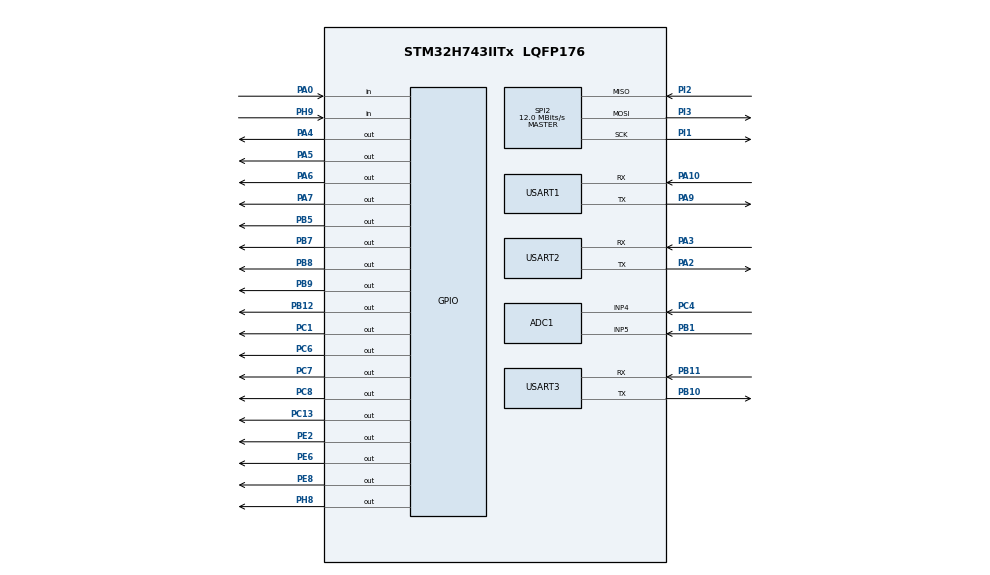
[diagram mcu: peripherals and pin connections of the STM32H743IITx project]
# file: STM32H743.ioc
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ADC1.Channel-0\#ChannelRegularConversion=ADC_CHANNEL_4
ADC1.ClockPrescaler=ADC_CLOCK_ASYNC_DIV1
ADC1.ConversionDataManagement=ADC_CONVERSIONDATA_DMA_ONESHOT
ADC1.ExternalTrigConv=ADC_EXTERNALTRIG_T3_TRGO
ADC1.NbrOfConversion=1
ADC1.NbrOfConversionFlag=1
ADC1.OffsetNumber-0\#ChannelRegularConversion=ADC_OFFSET_NONE
ADC1.OffsetSignedSaturation-0\#ChannelRegularConversion=DISABLE
ADC1.Rank-0\#ChannelRegularConversion=1
ADC1.SamplingTime-0\#ChannelRegularConversion=ADC_SAMPLETIME_8CYCLES_5
ADC1.master=1
CORTEX_M7.CPU_DCache=Disabled
CORTEX_M7.CPU_ICache=Disabled
CORTEX_M7.MPU_Control=__NULL
Dma.ADC1.0.Direction=DMA_PERIPH_TO_MEMORY
Dma.ADC1.0.EventEnable=DISABLE
Dma.ADC1.0.FIFOMode=DMA_FIFOMODE_DISABLE
Dma.ADC1.0.Instance=DMA1_Stream0
Dma.ADC1.0.MemDataAlignment=DMA_MDATAALIGN_HALFWORD
Dma.ADC1.0.MemInc=DMA_MINC_ENABLE
Dma.ADC1.0.Mode=DMA_NORMAL
Dma.ADC1.0.PeriphDataAlignment=DMA_PDATAALIGN_HALFWORD
Dma.ADC1.0.PeriphInc=DMA_PINC_DISABLE
Dma.ADC1.0.Polarity=HAL_DMAMUX_REQ_GEN_RISING
Dma.ADC1.0.Priority=DMA_PRIORITY_LOW
Dma.ADC1.0.RequestNumber=1
Dma.ADC1.0.SignalID=NONE
Dma.ADC1.0.SyncEnable=DISABLE
Dma.ADC1.0.SyncPolarity=HAL_DMAMUX_SYNC_NO_EVENT
Dma.ADC1.0.SyncRequestNumber=1
Dma.ADC1.0.SyncSignalID=NONE
Dma.Request0=ADC1
Mcu.Family=STM32H7
Mcu.Name=STM32H743IITx
Mcu.Package=LQFP176
NVIC.DMA1_Stream0_IRQn=true\:0\:0\:false\:false\:true\:false\:true\:true
NVIC.PriorityGroup=NVIC_PRIORITYGROUP_4
NVIC.USART2_IRQn=true\:0\:0\:false\:false\:true\:true\:true\:true
PA0.Signal=GPIO_Input
PA10.Mode=Asynchronous
PA10.Signal=USART1_RX
PA13\ (JTMS/SWDIO).Mode=Serial_Wire
PA13\ (JTMS/SWDIO).Signal=DEBUG_JTMS-SWDIO
PA14\ (JTCK/SWCLK).Mode=Serial_Wire
PA14\ (JTCK/SWCLK).Signal=DEBUG_JTCK-SWCLK
PA2.Mode=Asynchronous
PA2.Signal=USART2_TX
PA3.Mode=Asynchronous
PA3.Signal=USART2_RX
PA4.GPIO_Speed=GPIO_SPEED_FREQ_VERY_HIGH
PA4.PinState=GPIO_PIN_SET
PA4.Signal=GPIO_Output
PA5.Signal=GPIO_Output
PA6.Signal=GPIO_Output
PA7.GPIO_Speed=GPIO_SPEED_FREQ_VERY_HIGH
PA7.Signal=GPIO_Output
PA9.Mode=Asynchronous
PA9.Signal=USART1_TX
PB1.Signal=ADCx_INP5
PB10.Mode=Asynchronous
PB10.Signal=USART3_TX
PB11.Mode=Asynchronous
PB11.Signal=USART3_RX
PB12.GPIO_Speed=GPIO_SPEED_FREQ_HIGH
PB12.PinState=GPIO_PIN_SET
PB12.Signal=GPIO_Output
PB5.Signal=GPIO_Output
PB7.Signal=GPIO_Output
PB8.Signal=GPIO_Output
PB9.PinState=GPIO_PIN_SET
PB9.Signal=GPIO_Output
PC1.Signal=GPIO_Output
PC13.Signal=GPIO_Output
PC14-OSC32_IN\ (OSC32_IN).Mode=LSE-External-Oscillator
PC14-OSC32_IN\ (OSC32_IN).Signal=RCC_OSC32_IN
PC15-OSC32_OUT\ (OSC32_OUT).Mode=LSE-External-Oscillator
PC15-OSC32_OUT\ (OSC32_OUT).Signal=RCC_OSC32_OUT
PC4.Signal=ADCx_INP4
PC6.Signal=GPIO_Output
PC7.Signal=GPIO_Output
PC8.Signal=GPIO_Output
PD7.Signal=SPI1_MOSI
PE2.GPIO_Speed=GPIO_SPEED_FREQ_HIGH
PE2.Signal=GPIO_Output
PE6.GPIO_Speed=GPIO_SPEED_FREQ_HIGH
PE6.Signal=GPIO_Output
PE8.GPIO_PuPd=GPIO_PULLUP
PE8.PinState=GPIO_PIN_SET
PE8.Signal=GPIO_Output
PH0-OSC_IN\ (PH0).Mode=HSE-External-Oscillator
PH0-OSC_IN\ (PH0).Signal=RCC_OSC_IN
PH1-OSC_OUT\ (PH1).Mode=HSE-External-Oscillator
PH1-OSC_OUT\ (PH1).Signal=RCC_OSC_OUT
PH8.GPIO_Speed=GPIO_SPEED_FREQ_VERY_HIGH
PH8.Signal=GPIO_Output
PH9.Signal=GPIO_Input
PI1.GPIO_Speed=GPIO_SPEED_FREQ_HIGH
PI1.Mode=Full_Duplex_Master
PI1.Signal=SPI2_SCK
PI2.GPIO_Speed=GPIO_SPEED_FREQ_HIGH
PI2.Mode=Full_Duplex_Master
PI2.Signal=SPI2_MISO
PI3.GPIO_Speed=GPIO_SPEED_FREQ_HIGH
PI3.Mode=Full_Duplex_Master
PI3.Signal=SPI2_MOSI
ProjectManager.HeapSize=0x200
ProjectManager.StackSize=0x4000
ProjectManager.TargetToolchain=MDK-ARM V5.32
RCC.ADCFreq_Value=75000000
RCC.APB1Freq_Value=120000000
RCC.APB2Freq_Value=120000000
RCC.APB3Freq_Value=120000000
RCC.APB4Freq_Value=120000000
RCC.CortexFreq_Value=480000000
RCC.D1PPRE=RCC_APB3_DIV2
RCC.D2PPRE1=RCC_APB1_DIV2
RCC.D2PPRE2=RCC_APB2_DIV2
RCC.D3PPRE=RCC_APB4_DIV2
RCC.DIVM1=5
RCC.DIVM2=2
RCC.DIVN1=192
RCC.DIVN2=12
RCC.DIVQ1=5
RCC.HCLKFreq_Value=240000000
RCC.HPRE=RCC_HCLK_DIV2
RCC.PLL2FRACN=0
RCC.PLLFRACN=0
RCC.PLLSourceVirtual=RCC_PLLSOURCE_HSE
RCC.SYSCLKFreq_VALUE=480000000
RCC.SYSCLKSource=RCC_SYSCLKSOURCE_PLLCLK
RCC.USBFreq_Value=192000000
SH.ADCx_INP4.0=ADC1_INP4,IN4-Single-Ended
SH.ADCx_INP5.0=ADC1_INP5,IN5-Single-Ended
SPI2.BaudRatePrescaler=SPI_BAUDRATEPRESCALER_16
SPI2.CLKPhase=SPI_PHASE_2EDGE
SPI2.CalculateBaudRate=12.0 MBits/s
SPI2.DataSize=SPI_DATASIZE_20BIT
SPI2.Direction=SPI_DIRECTION_2LINES
SPI2.Mode=SPI_MODE_MASTER
SPI2.NSSPMode=SPI_NSS_PULSE_DISABLE
SPI2.VirtualType=VM_MASTER
TIM3.Period=1000-1
TIM3.Prescaler=12-1
TIM3.TIM_MasterOutputTrigger=TIM_TRGO_UPDATE
USART1.VirtualMode-Asynchronous=VM_ASYNC
USART2.VirtualMode-Asynchronous=VM_ASYNC
USART3.VirtualMode-Asynchronous=VM_ASYNC
VP_MEMORYMAP_VS_MEMORYMAP.Mode=CurAppReg
VP_TIM3_VS_ClockSourceINT.Mode=Internal
board=custom

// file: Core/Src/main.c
/* USER CODE BEGIN Header */
/**
  ******************************************************************************
  * @file           : main.c
  * @brief          : Main program body
  ******************************************************************************
  * @attention
  *
  * Copyright (c) 2026 STMicroelectronics.
  * All rights reserved.
  *
  * This software is licensed under terms that can be found in the LICENSE file
  * in the root directory of this software component.
  * If no LICENSE file comes with this software, it is provided AS-IS.
  *
  ******************************************************************************
  */
/* USER CODE END Header */
#include "main.h"
#include "adc.h"
#include "dma.h"
#include "spi.h"
#include "tim.h"
#include "usart.h"
#include "gpio.h"

void SystemClock_Config(void);

/**
  * @brief  通用库工程入口。
  * @retval 正常运行时不返回。
  */
int main(void)
{

  /* MCU Configuration--------------------------------------------------------*/

  /* Reset of all peripherals, Initializes the Flash interface and the Systick. */
  HAL_Init();

  /* Configure the system clock */
  SystemClock_Config();

  /* Initialize all configured peripherals */
  MX_GPIO_Init();
  MX_DMA_Init();
  MX_USART3_UART_Init();
  MX_ADC1_Init();
  MX_SPI2_Init();
  MX_TIM3_Init();
  MX_USART1_UART_Init();
  MX_USART2_UART_Init();
  /* USER CODE BEGIN 2 */
  /* 通用库工程不自动启动设备，由具体题目按需调用APP层接口。 */
  /* USER CODE END 2 */

  /* Infinite loop */
  while (1)
  {

  }
}

/**
  * @brief  配置STM32H743系统时钟。
  * @retval 无。
  */
void SystemClock_Config(void)
{
  RCC_OscInitTypeDef RCC_OscInitStruct = {0};
  RCC_ClkInitTypeDef RCC_ClkInitStruct = {0};

  /** Supply configuration update enable
  */
  HAL_PWREx_ConfigSupply(PWR_LDO_SUPPLY);

  /** Configure the main internal regulator output voltage
  */
  __HAL_PWR_VOLTAGESCALING_CONFIG(PWR_REGULATOR_VOLTAGE_SCALE0);

  while(!__HAL_PWR_GET_FLAG(PWR_FLAG_VOSRDY)) {}

  /** Initializes the RCC Oscillators according to the specified parameters
  * in the RCC_OscInitTypeDef structure.
  */
  RCC_OscInitStruct.OscillatorType = RCC_OSCILLATORTYPE_HSE;
  RCC_OscInitStruct.HSEState = RCC_HSE_ON;
  RCC_OscInitStruct.PLL.PLLState = RCC_PLL_ON;
  RCC_OscInitStruct.PLL.PLLSource = RCC_PLLSOURCE_HSE;
  RCC_OscInitStruct.PLL.PLLM = 5;
  RCC_OscInitStruct.PLL.PLLN = 192;
  RCC_OscInitStruct.PLL.PLLP = 2;
  RCC_OscInitStruct.PLL.PLLQ = 5;
  RCC_OscInitStruct.PLL.PLLR = 2;
  RCC_OscInitStruct.PLL.PLLRGE = RCC_PLL1VCIRANGE_2;
  RCC_OscInitStruct.PLL.PLLVCOSEL = RCC_PLL1VCOWIDE;
  RCC_OscInitStruct.PLL.PLLFRACN = 0;
  if (HAL_RCC_OscConfig(&RCC_OscInitStruct) != HAL_OK)
  {
    Error_Handler();
  }

  /** Initializes the CPU, AHB and APB buses clocks
  */
  RCC_ClkInitStruct.ClockType = RCC_CLOCKTYPE_HCLK|RCC_CLOCKTYPE_SYSCLK
                              |RCC_CLOCKTYPE_PCLK1|RCC_CLOCKTYPE_PCLK2
                              |RCC_CLOCKTYPE_D3PCLK1|RCC_CLOCKTYPE_D1PCLK1;
  RCC_ClkInitStruct.SYSCLKSource = RCC_SYSCLKSOURCE_PLLCLK;
  RCC_ClkInitStruct.SYSCLKDivider = RCC_SYSCLK_DIV1;
  RCC_ClkInitStruct.AHBCLKDivider = RCC_HCLK_DIV2;
  RCC_ClkInitStruct.APB3CLKDivider = RCC_APB3_DIV2;
  RCC_ClkInitStruct.APB1CLKDivider = RCC_APB1_DIV2;
  RCC_ClkInitStruct.APB2CLKDivider = RCC_APB2_DIV2;
  RCC_ClkInitStruct.APB4CLKDivider = RCC_APB4_DIV2;

  if (HAL_RCC_ClockConfig(&RCC_ClkInitStruct, FLASH_LATENCY_4) != HAL_OK)
  {
    Error_Handler();
  }
}

/**
  * @brief  出现不可恢复错误时停止运行。
  * @retval 无。
  */
void Error_Handler(void)
{
  __disable_irq();
  while (1)
  {
  }
}
